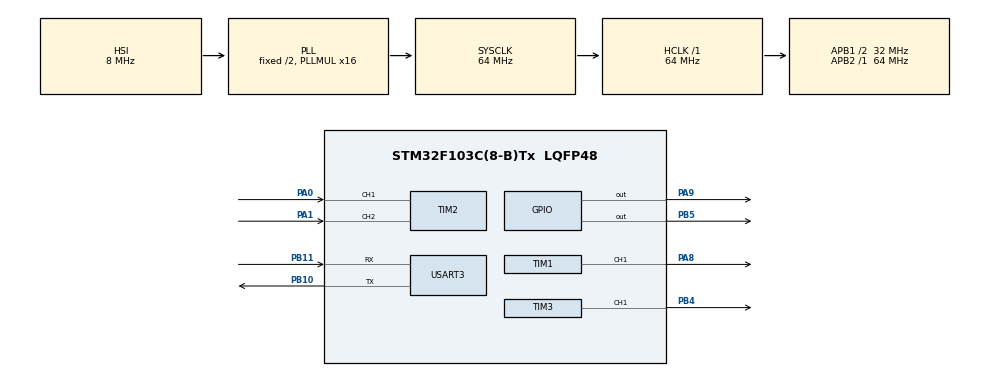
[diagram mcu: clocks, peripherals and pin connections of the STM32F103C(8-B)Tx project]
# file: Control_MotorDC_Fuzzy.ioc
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Mcu.Family=STM32F1
Mcu.Name=STM32F103C(8-B)Tx
Mcu.Package=LQFP48
NVIC.PriorityGroup=NVIC_PRIORITYGROUP_4
PA0-WKUP.Signal=S_TIM2_CH1_ETR
PA1.Signal=S_TIM2_CH2
PA13.Mode=Serial_Wire
PA13.Signal=SYS_JTMS-SWDIO
PA14.Mode=Serial_Wire
PA14.Signal=SYS_JTCK-SWCLK
PA8.Signal=S_TIM1_CH1
PA9.Signal=GPIO_Output
PB10.Mode=Asynchronous
PB10.Signal=USART3_TX
PB11.Mode=Asynchronous
PB11.Signal=USART3_RX
PB4.Signal=S_TIM3_CH1
PB5.Signal=GPIO_Output
ProjectManager.HeapSize=0x200
ProjectManager.StackSize=0x400
ProjectManager.TargetToolchain=STM32CubeIDE
RCC.AHBFreq_Value=64000000
RCC.APB1CLKDivider=RCC_HCLK_DIV2
RCC.APB1Freq_Value=32000000
RCC.APB1TimFreq_Value=64000000
RCC.APB2Freq_Value=64000000
RCC.APB2TimFreq_Value=64000000
RCC.HCLKFreq_Value=64000000
RCC.PLLMUL=RCC_PLL_MUL16
RCC.SYSCLKFreq_VALUE=64000000
RCC.SYSCLKSource=RCC_SYSCLKSOURCE_PLLCLK
RCC.USBFreq_Value=64000000
SH.S_TIM1_CH1.0=TIM1_CH1,PWM Generation1 CH1
SH.S_TIM2_CH1_ETR.0=TIM2_CH1,Encoder_Interface
SH.S_TIM2_CH2.0=TIM2_CH2,Encoder_Interface
SH.S_TIM3_CH1.0=TIM3_CH1,PWM Generation1 CH1
TIM1.Channel-PWM\ Generation1\ CH1=TIM_CHANNEL_1
TIM1.Period=399
TIM1.Prescaler=15
TIM3.Channel-PWM\ Generation1\ CH1=TIM_CHANNEL_1
TIM3.Period=399
TIM3.Prescaler=15
TIM4.Period=1999
TIM4.Prescaler=319
USART3.VirtualMode=VM_ASYNC
VP_TIM4_VS_ClockSourceINT.Mode=Internal
board=custom

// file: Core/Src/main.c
/* USER CODE BEGIN Header */
/**
  ******************************************************************************
  * @file           : main.c
  * @brief          : Main program body
  ******************************************************************************
  * @attention
  *
  * <h2><center>&copy; Copyright (c) 2023 STMicroelectronics.
  * All rights reserved.</center></h2>
  *
  * This software component is licensed by ST under BSD 3-Clause license,
  * the "License"; You may not use this file except in compliance with the
  * License. You may obtain a copy of the License at:
  *                        opensource.org/licenses/BSD-3-Clause
  *
  ******************************************************************************
  */
/* USER CODE END Header */
#include "main.h"

/* USER CODE BEGIN Includes */
#include <motor.h>
#include <fuzzy_fis.h>
/* USER CODE END Includes */

TIM_HandleTypeDef htim1;
TIM_HandleTypeDef htim2;
TIM_HandleTypeDef htim3;
TIM_HandleTypeDef htim4;

UART_HandleTypeDef huart3;

/* USER CODE BEGIN PV */
Parameter_controller_t		t_parameter_controller;
uint8_t		u8_flag_10ms = 0;
/* USER CODE END PV */

void SystemClock_Config(void);
static void MX_GPIO_Init(void);
static void MX_TIM2_Init(void);
static void MX_TIM1_Init(void);
static void MX_TIM3_Init(void);
static void MX_TIM4_Init(void);
static void MX_USART3_UART_Init(void);

/* USER CODE BEGIN 0 */

void HAL_TIM_PeriodElapsedCallback(TIM_HandleTypeDef *htim)
{
	if(htim->Instance==TIM4)
	{
		u8_flag_10ms = 1;
	}
}

/* USER CODE END 0 */

int main(void)
{
  /* USER CODE BEGIN 1 */
	Init_parameter(1000, &t_parameter_controller);
	fuzzy_init();
  /* USER CODE END 1 */

  /* MCU Configuration--------------------------------------------------------*/

  /* Reset of all peripherals, Initializes the Flash interface and the Systick. */
  HAL_Init();

  /* Configure the system clock */
  SystemClock_Config();

  /* Initialize all configured peripherals */
  MX_GPIO_Init();
  MX_TIM2_Init();
  MX_TIM1_Init();
  MX_TIM3_Init();
  MX_TIM4_Init();
  MX_USART3_UART_Init();

  /* Infinite loop */
  while (1)
  {

    /* USER CODE BEGIN 3 */
	  if (u8_flag_10ms)
	  	  {
	  		u8_flag_10ms = 0;
	  		Controller (Read_enc (&(t_parameter_controller.i_pre_cnt)), &t_parameter_controller);

	  	  }
  }
  /* USER CODE END 3 */
}

void SystemClock_Config(void)
{
  RCC_OscInitTypeDef RCC_OscInitStruct = {0};
  RCC_ClkInitTypeDef RCC_ClkInitStruct = {0};

  /** Initializes the RCC Oscillators according to the specified parameters
  * in the RCC_OscInitTypeDef structure.
  */
  RCC_OscInitStruct.OscillatorType = RCC_OSCILLATORTYPE_HSI;
  RCC_OscInitStruct.HSIState = RCC_HSI_ON;
  RCC_OscInitStruct.HSICalibrationValue = RCC_HSICALIBRATION_DEFAULT;
  RCC_OscInitStruct.PLL.PLLState = RCC_PLL_ON;
  RCC_OscInitStruct.PLL.PLLSource = RCC_PLLSOURCE_HSI_DIV2;
  RCC_OscInitStruct.PLL.PLLMUL = RCC_PLL_MUL16;
  if (HAL_RCC_OscConfig(&RCC_OscInitStruct) != HAL_OK)
  {
    Error_Handler();
  }
  /** Initializes the CPU, AHB and APB buses clocks
  */
  RCC_ClkInitStruct.ClockType = RCC_CLOCKTYPE_HCLK|RCC_CLOCKTYPE_SYSCLK
                              |RCC_CLOCKTYPE_PCLK1|RCC_CLOCKTYPE_PCLK2;
  RCC_ClkInitStruct.SYSCLKSource = RCC_SYSCLKSOURCE_PLLCLK;
  RCC_ClkInitStruct.AHBCLKDivider = RCC_SYSCLK_DIV1;
  RCC_ClkInitStruct.APB1CLKDivider = RCC_HCLK_DIV2;
  RCC_ClkInitStruct.APB2CLKDivider = RCC_HCLK_DIV1;

  if (HAL_RCC_ClockConfig(&RCC_ClkInitStruct, FLASH_LATENCY_2) != HAL_OK)
  {
    Error_Handler();
  }
}

static void MX_TIM1_Init(void)
{

  TIM_MasterConfigTypeDef sMasterConfig = {0};
  TIM_OC_InitTypeDef sConfigOC = {0};
  TIM_BreakDeadTimeConfigTypeDef sBreakDeadTimeConfig = {0};

  htim1.Instance = TIM1;
  htim1.Init.Prescaler = 15;
  htim1.Init.CounterMode = TIM_COUNTERMODE_UP;
  htim1.Init.Period = 399;
  htim1.Init.ClockDivision = TIM_CLOCKDIVISION_DIV1;
  htim1.Init.RepetitionCounter = 0;
  htim1.Init.AutoReloadPreload = TIM_AUTORELOAD_PRELOAD_DISABLE;
  if (HAL_TIM_PWM_Init(&htim1) != HAL_OK)
  {
    Error_Handler();
  }
  sMasterConfig.MasterOutputTrigger = TIM_TRGO_RESET;
  sMasterConfig.MasterSlaveMode = TIM_MASTERSLAVEMODE_DISABLE;
  if (HAL_TIMEx_MasterConfigSynchronization(&htim1, &sMasterConfig) != HAL_OK)
  {
    Error_Handler();
  }
  sConfigOC.OCMode = TIM_OCMODE_PWM1;
  sConfigOC.Pulse = 0;
  sConfigOC.OCPolarity = TIM_OCPOLARITY_HIGH;
  sConfigOC.OCNPolarity = TIM_OCNPOLARITY_HIGH;
  sConfigOC.OCFastMode = TIM_OCFAST_DISABLE;
  sConfigOC.OCIdleState = TIM_OCIDLESTATE_RESET;
  sConfigOC.OCNIdleState = TIM_OCNIDLESTATE_RESET;
  if (HAL_TIM_PWM_ConfigChannel(&htim1, &sConfigOC, TIM_CHANNEL_1) != HAL_OK)
  {
    Error_Handler();
  }
  sBreakDeadTimeConfig.OffStateRunMode = TIM_OSSR_DISABLE;
  sBreakDeadTimeConfig.OffStateIDLEMode = TIM_OSSI_DISABLE;
  sBreakDeadTimeConfig.LockLevel = TIM_LOCKLEVEL_OFF;
  sBreakDeadTimeConfig.DeadTime = 0;
  sBreakDeadTimeConfig.BreakState = TIM_BREAK_DISABLE;
  sBreakDeadTimeConfig.BreakPolarity = TIM_BREAKPOLARITY_HIGH;
  sBreakDeadTimeConfig.AutomaticOutput = TIM_AUTOMATICOUTPUT_DISABLE;
  if (HAL_TIMEx_ConfigBreakDeadTime(&htim1, &sBreakDeadTimeConfig) != HAL_OK)
  {
    Error_Handler();
  }
  HAL_TIM_MspPostInit(&htim1);

}

static void MX_TIM2_Init(void)
{

  TIM_Encoder_InitTypeDef sConfig = {0};
  TIM_MasterConfigTypeDef sMasterConfig = {0};

  htim2.Instance = TIM2;
  htim2.Init.Prescaler = 0;
  htim2.Init.CounterMode = TIM_COUNTERMODE_UP;
  htim2.Init.Period = 65535;
  htim2.Init.ClockDivision = TIM_CLOCKDIVISION_DIV1;
  htim2.Init.AutoReloadPreload = TIM_AUTORELOAD_PRELOAD_DISABLE;
  sConfig.EncoderMode = TIM_ENCODERMODE_TI1;
  sConfig.IC1Polarity = TIM_ICPOLARITY_RISING;
  sConfig.IC1Selection = TIM_ICSELECTION_DIRECTTI;
  sConfig.IC1Prescaler = TIM_ICPSC_DIV1;
  sConfig.IC1Filter = 0;
  sConfig.IC2Polarity = TIM_ICPOLARITY_RISING;
  sConfig.IC2Selection = TIM_ICSELECTION_DIRECTTI;
  sConfig.IC2Prescaler = TIM_ICPSC_DIV1;
  sConfig.IC2Filter = 0;
  if (HAL_TIM_Encoder_Init(&htim2, &sConfig) != HAL_OK)
  {
    Error_Handler();
  }
  sMasterConfig.MasterOutputTrigger = TIM_TRGO_RESET;
  sMasterConfig.MasterSlaveMode = TIM_MASTERSLAVEMODE_DISABLE;
  if (HAL_TIMEx_MasterConfigSynchronization(&htim2, &sMasterConfig) != HAL_OK)
  {
    Error_Handler();
  }

}

static void MX_TIM3_Init(void)
{

  TIM_MasterConfigTypeDef sMasterConfig = {0};
  TIM_OC_InitTypeDef sConfigOC = {0};

  htim3.Instance = TIM3;
  htim3.Init.Prescaler = 15;
  htim3.Init.CounterMode = TIM_COUNTERMODE_UP;
  htim3.Init.Period = 399;
  htim3.Init.ClockDivision = TIM_CLOCKDIVISION_DIV1;
  htim3.Init.AutoReloadPreload = TIM_AUTORELOAD_PRELOAD_DISABLE;
  if (HAL_TIM_PWM_Init(&htim3) != HAL_OK)
  {
    Error_Handler();
  }
  sMasterConfig.MasterOutputTrigger = TIM_TRGO_RESET;
  sMasterConfig.MasterSlaveMode = TIM_MASTERSLAVEMODE_DISABLE;
  if (HAL_TIMEx_MasterConfigSynchronization(&htim3, &sMasterConfig) != HAL_OK)
  {
    Error_Handler();
  }
  sConfigOC.OCMode = TIM_OCMODE_PWM1;
  sConfigOC.Pulse = 0;
  sConfigOC.OCPolarity = TIM_OCPOLARITY_HIGH;
  sConfigOC.OCFastMode = TIM_OCFAST_DISABLE;
  if (HAL_TIM_PWM_ConfigChannel(&htim3, &sConfigOC, TIM_CHANNEL_1) != HAL_OK)
  {
    Error_Handler();
  }
  HAL_TIM_MspPostInit(&htim3);

}

static void MX_TIM4_Init(void)
{

  TIM_ClockConfigTypeDef sClockSourceConfig = {0};
  TIM_MasterConfigTypeDef sMasterConfig = {0};

  htim4.Instance = TIM4;
  htim4.Init.Prescaler = 319;
  htim4.Init.CounterMode = TIM_COUNTERMODE_UP;
  htim4.Init.Period = 1999;
  htim4.Init.ClockDivision = TIM_CLOCKDIVISION_DIV1;
  htim4.Init.AutoReloadPreload = TIM_AUTORELOAD_PRELOAD_DISABLE;
  if (HAL_TIM_Base_Init(&htim4) != HAL_OK)
  {
    Error_Handler();
  }
  sClockSourceConfig.ClockSource = TIM_CLOCKSOURCE_INTERNAL;
  if (HAL_TIM_ConfigClockSource(&htim4, &sClockSourceConfig) != HAL_OK)
  {
    Error_Handler();
  }
  sMasterConfig.MasterOutputTrigger = TIM_TRGO_RESET;
  sMasterConfig.MasterSlaveMode = TIM_MASTERSLAVEMODE_DISABLE;
  if (HAL_TIMEx_MasterConfigSynchronization(&htim4, &sMasterConfig) != HAL_OK)
  {
    Error_Handler();
  }

}

static void MX_USART3_UART_Init(void)
{

  huart3.Instance = USART3;
  huart3.Init.BaudRate = 115200;
  huart3.Init.WordLength = UART_WORDLENGTH_8B;
  huart3.Init.StopBits = UART_STOPBITS_1;
  huart3.Init.Parity = UART_PARITY_NONE;
  huart3.Init.Mode = UART_MODE_TX_RX;
  huart3.Init.HwFlowCtl = UART_HWCONTROL_NONE;
  huart3.Init.OverSampling = UART_OVERSAMPLING_16;
  if (HAL_UART_Init(&huart3) != HAL_OK)
  {
    Error_Handler();
  }

}

static void MX_GPIO_Init(void)
{
  GPIO_InitTypeDef GPIO_InitStruct = {0};

  /* GPIO Ports Clock Enable */
  __HAL_RCC_GPIOA_CLK_ENABLE();
  __HAL_RCC_GPIOB_CLK_ENABLE();

  /*Configure GPIO pin Output Level */
  HAL_GPIO_WritePin(GPIOA, GPIO_PIN_9, GPIO_PIN_RESET);

  /*Configure GPIO pin Output Level */
  HAL_GPIO_WritePin(GPIOB, GPIO_PIN_5, GPIO_PIN_RESET);

  /*Configure GPIO pin : PA9 */
  GPIO_InitStruct.Pin = GPIO_PIN_9;
  GPIO_InitStruct.Mode = GPIO_MODE_OUTPUT_PP;
  GPIO_InitStruct.Pull = GPIO_NOPULL;
  GPIO_InitStruct.Speed = GPIO_SPEED_FREQ_LOW;
  HAL_GPIO_Init(GPIOA, &GPIO_InitStruct);

  /*Configure GPIO pin : PB5 */
  GPIO_InitStruct.Pin = GPIO_PIN_5;
  GPIO_InitStruct.Mode = GPIO_MODE_OUTPUT_PP;
  GPIO_InitStruct.Pull = GPIO_NOPULL;
  GPIO_InitStruct.Speed = GPIO_SPEED_FREQ_LOW;
  HAL_GPIO_Init(GPIOB, &GPIO_InitStruct);

}

void Error_Handler(void)
{
  __disable_irq();
  while (1)
  {
  }
}

/************************ (C) COPYRIGHT STMicroelectronics *****END OF FILE****/
